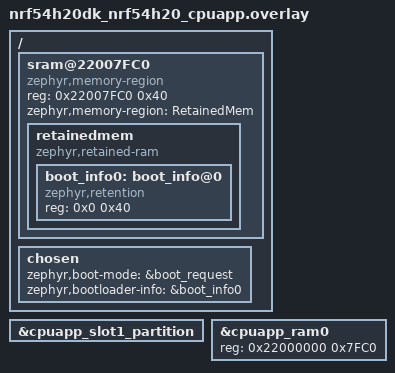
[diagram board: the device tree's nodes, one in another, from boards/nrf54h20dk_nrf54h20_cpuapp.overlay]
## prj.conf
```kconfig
# Enable MCUmgr and dependencies.
CONFIG_NET_BUF=y
CONFIG_ZCBOR=y
CONFIG_CRC=y
CONFIG_MCUMGR=y
CONFIG_STREAM_FLASH=y
CONFIG_FLASH_MAP=y

# Some command handlers require a large stack.
CONFIG_SYSTEM_WORKQUEUE_STACK_SIZE=2304
CONFIG_MAIN_STACK_SIZE=2176

# Ensure an MCUboot-compatible binary is generated.
CONFIG_BOOTLOADER_MCUBOOT=y

# Enable flash operations.
CONFIG_FLASH=y

# Required by the `taskstat` command.
CONFIG_THREAD_MONITOR=y

# Support for taskstat command
CONFIG_MCUMGR_GRP_OS_TASKSTAT=y

# Enable statistics and statistic names.
CONFIG_STATS=y
CONFIG_STATS_NAMES=y

# Enable most core commands.
CONFIG_FLASH=y
CONFIG_IMG_MANAGER=y
CONFIG_MCUMGR_GRP_IMG=y
CONFIG_MCUMGR_GRP_IMG_NRF=y
CONFIG_MCUMGR_GRP_OS=y
CONFIG_MCUMGR_GRP_STAT=y

# Enable logging
CONFIG_LOG=y
CONFIG_MCUBOOT_UTIL_LOG_LEVEL_WRN=y

# Disable debug logging
CONFIG_LOG_MAX_LEVEL=3

# Enable boot requests.
CONFIG_NRF_MCUBOOT_BOOT_REQUEST=y

# Enable DK LED/button library
CONFIG_DK_LIBRARY=y

# Configure bluetooth

CONFIG_BT=y
CONFIG_BT_PERIPHERAL=y

# Allow for large Bluetooth data packets.
CONFIG_BT_L2CAP_TX_MTU=498
CONFIG_BT_BUF_ACL_RX_SIZE=502
CONFIG_BT_BUF_ACL_TX_SIZE=502

# Enable the Bluetooth mcumgr transport (unauthenticated).
CONFIG_MCUMGR_TRANSPORT_BT=y
CONFIG_MCUMGR_TRANSPORT_BT_CONN_PARAM_CONTROL=y

# Enable the Shell mcumgr transport.
CONFIG_BASE64=y
CONFIG_CRC=y
CONFIG_SHELL=y
CONFIG_SHELL_BACKEND_SERIAL=y
CONFIG_MCUMGR_TRANSPORT_SHELL=y

# Enable the mcumgr Packet Reassembly feature over Bluetooth and its configuration dependencies.
# MCUmgr buffer size is optimized to fit one SMP packet divided into five Bluetooth Write Commands,
# transmitted with the maximum possible MTU value: 498 bytes.
CONFIG_MCUMGR_TRANSPORT_BT_REASSEMBLY=y
CONFIG_MCUMGR_TRANSPORT_NETBUF_SIZE=2475
CONFIG_MCUMGR_GRP_OS_MCUMGR_PARAMS=y
CONFIG_MCUMGR_TRANSPORT_WORKQUEUE_STACK_SIZE=4608

# Enable the LittleFS file system.
CONFIG_FILE_SYSTEM=y
CONFIG_FILE_SYSTEM_LITTLEFS=y

# Enable file system commands
CONFIG_MCUMGR_GRP_FS=y

# Enable the storage erase command.
CONFIG_MCUMGR_GRP_ZBASIC=y
CONFIG_MCUMGR_GRP_ZBASIC_STORAGE_ERASE=y

# Disable Bluetooth ping support
CONFIG_BT_CTLR_LE_PING=n

# Disable shell commands that are not needed
CONFIG_CLOCK_CONTROL_NRF_SHELL=n
CONFIG_DEVICE_SHELL=n
CONFIG_DEVMEM_SHELL=n
CONFIG_FLASH_SHELL=n

CONFIG_RETAINED_MEM=y
CONFIG_RETENTION=y
CONFIG_RETENTION_BOOTLOADER_INFO=y
CONFIG_RETENTION_BOOTLOADER_INFO_TYPE_MCUBOOT=y
```

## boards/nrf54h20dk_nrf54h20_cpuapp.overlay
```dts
/*
 * Copyright (c) 2025 Nordic Semiconductor ASA
 *
 * SPDX-License-Identifier: LicenseRef-Nordic-5-Clause
 */

#include "../sysbuild/nrf54h20dk_nrf54h20_memory_map.dtsi"

/ {
	sram@22007FC0 {
		compatible = "zephyr,memory-region", "mmio-sram";
		reg = <0x22007FC0 0x40>;
		zephyr,memory-region = "RetainedMem";
		status = "okay";

		retainedmem {
			compatible = "zephyr,retained-ram";
			status = "okay";
			#address-cells = <1>;
			#size-cells = <1>;

			boot_info0: boot_info@0 {
				compatible = "zephyr,retention";
				status = "okay";
				reg = <0x0 0x40>;
			};
		};
	};
	chosen {
		zephyr,boot-mode = &boot_request;
		zephyr,bootloader-info = &boot_info0;
	};
};

secondary_app_partition: &cpuapp_slot1_partition {};

&cpuapp_ram0 {
	reg = <0x22000000 0x7FC0>;
};
```

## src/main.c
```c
/*
 * Copyright (c) 2012-2014 Wind River Systems, Inc.
 * Copyright (c) 2020 Prevas A/S
 * Copyright (c) 2025 Nordic Semiconductor ASA
 *
 * SPDX-License-Identifier: LicenseRef-Nordic-5-Clause
 */

#include <zephyr/kernel.h>
#include <common.h>
#include "ab_utils.h"

#include <zephyr/retention/blinfo.h>
#include <bootutil/image.h>

#define LOG_LEVEL LOG_LEVEL_DBG
#include <zephyr/logging/log.h>
LOG_MODULE_REGISTER(ab_sample);

static void blinfo_bootloader_version(void)
{
	struct image_version version = {0x00};

	int ret = blinfo_lookup(BLINFO_BOOTLOADER_VERSION,
				(char *)&version,
				sizeof(struct image_version));


	if (ret < 0) {
		LOG_INF("blinfo_lookup error: %d", ret);

	} else {
		LOG_INF("bl iv_major: %d", version.iv_major);
		LOG_INF("bl iv_minor: %d", version.iv_minor);
		LOG_INF("bl iv_revision: %d", version.iv_revision);
		LOG_INF("bl iv_build_num: %d", version.iv_build_num);
	}
}

int main(void)
{
#ifdef CONFIG_MCUMGR_TRANSPORT_BT
	start_smp_bluetooth_adverts();
#endif

	/* Give BLE a moment to start up */
	k_sleep(K_MSEC(1000));

	ab_actions_perform();

	/* using __TIME__ ensure that a new binary will be built on every
	 * compile which is convenient when testing firmware upgrade.
	 */
	LOG_INF("build time: " __DATE__ " " __TIME__);

	blinfo_bootloader_version();

	/* The system work queue handles all incoming mcumgr requests.  Let the
	 * main thread idle while the mcumgr server runs.
	 */
	while (1) {
		k_sleep(K_MSEC(1000));
	}

	return 0;
}
```
